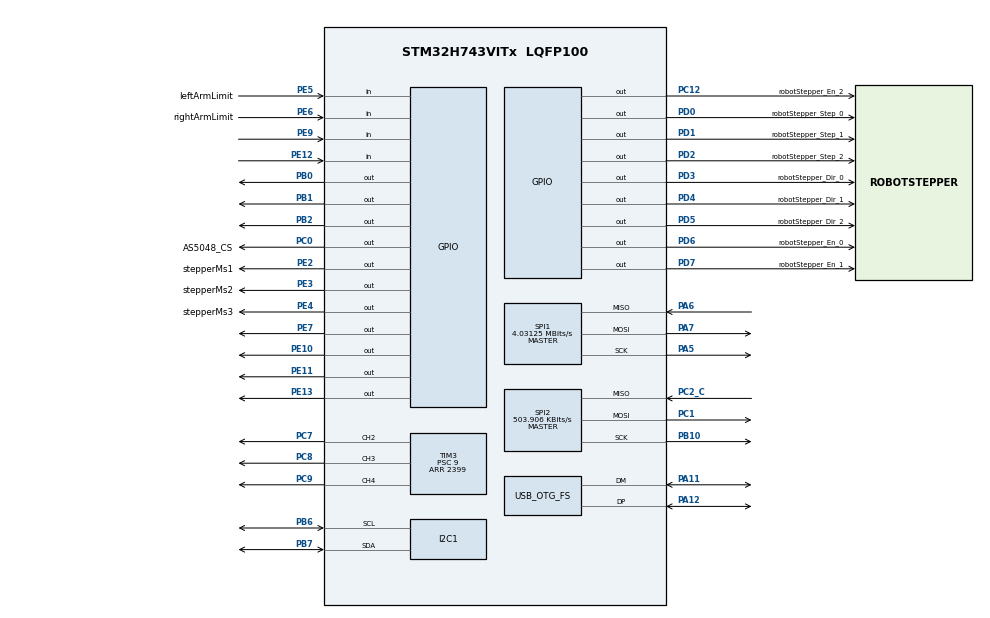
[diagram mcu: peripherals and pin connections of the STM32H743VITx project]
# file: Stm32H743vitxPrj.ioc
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FREERTOS.Tasks01=defaultTask,0,6001,StartDefaultTask,Default,NULL,Dynamic,NULL,NULL
FREERTOS.configMINIMAL_STACK_SIZE=6000
FREERTOS.configTICK_RATE_HZ=100
FREERTOS.configTOTAL_HEAP_SIZE=135360
I2C1.Timing=0x307075B1
Mcu.Family=STM32H7
Mcu.Name=STM32H743VITx
Mcu.Package=LQFP100
NVIC.OTG_FS_IRQn=true\:0\:0\:false\:false\:true\:false\:false\:true
NVIC.PriorityGroup=NVIC_PRIORITYGROUP_4
NVIC.TIM2_IRQn=true\:5\:0\:false\:false\:true\:true\:true\:true
NVIC.TIM5_IRQn=true\:0\:0\:false\:false\:true\:false\:true\:true
NVIC.TimeBase=TIM5_IRQn
NVIC.TimeBaseIP=TIM5
PA11.Mode=Device_Only
PA11.Signal=USB_OTG_FS_DM
PA12.Mode=Device_Only
PA12.Signal=USB_OTG_FS_DP
PA5.Mode=Full_Duplex_Master
PA5.Signal=SPI1_SCK
PA6.Mode=Full_Duplex_Master
PA6.Signal=SPI1_MISO
PA7.Mode=Full_Duplex_Master
PA7.Signal=SPI1_MOSI
PB0.Signal=GPIO_Output
PB1.Signal=GPIO_Output
PB10.Mode=Full_Duplex_Master
PB10.Signal=SPI2_SCK
PB2.Signal=GPIO_Output
PB6.Mode=I2C
PB6.Signal=I2C1_SCL
PB7.Mode=I2C
PB7.Signal=I2C1_SDA
PC0.GPIO_Label=AS5048_CS
PC0.Signal=GPIO_Output
PC1.Mode=Full_Duplex_Master
PC1.Signal=SPI2_MOSI
PC12.GPIO_Label=robotStepper_En_2
PC12.Signal=GPIO_Output
PC14-OSC32_IN\ (OSC32_IN).Mode=LSE-External-Oscillator
PC14-OSC32_IN\ (OSC32_IN).Signal=RCC_OSC32_IN
PC15-OSC32_OUT\ (OSC32_OUT).Mode=LSE-External-Oscillator
PC15-OSC32_OUT\ (OSC32_OUT).Signal=RCC_OSC32_OUT
PC2_C.Mode=Full_Duplex_Master
PC2_C.Signal=SPI2_MISO
PC7.Signal=S_TIM3_CH2
PC8.Signal=S_TIM3_CH3
PC9.Signal=S_TIM3_CH4
PD0.GPIO_Label=robotStepper_Step_0
PD0.Signal=GPIO_Output
PD1.GPIO_Label=robotStepper_Step_1
PD1.Signal=GPIO_Output
PD2.GPIO_Label=robotStepper_Step_2
PD2.Signal=GPIO_Output
PD3.GPIO_Label=robotStepper_Dir_0
PD3.Signal=GPIO_Output
PD4.GPIO_Label=robotStepper_Dir_1
PD4.Signal=GPIO_Output
PD5.GPIO_Label=robotStepper_Dir_2
PD5.Signal=GPIO_Output
PD6.GPIO_Label=robotStepper_En_0
PD6.Signal=GPIO_Output
PD7.GPIO_Label=robotStepper_En_1
PD7.Signal=GPIO_Output
PE10.Signal=GPIO_Output
PE11.Signal=GPIO_Output
PE12.Signal=GPIO_Input
PE13.Signal=GPIO_Output
PE2.GPIO_Label=stepperMs1
PE2.Signal=GPIO_Output
PE3.GPIO_Label=stepperMs2
PE3.Signal=GPIO_Output
PE4.GPIO_Label=stepperMs3
PE4.Signal=GPIO_Output
PE5.GPIO_Label=leftArmLimit
PE5.GPIO_PuPd=GPIO_PULLUP
PE5.Signal=GPIO_Input
PE6.GPIO_Label=rightArmLimit
PE6.GPIO_PuPd=GPIO_PULLUP
PE6.Signal=GPIO_Input
PE7.Signal=GPIO_Output
PE9.Signal=GPIO_Input
PH0-OSC_IN\ (PH0).Mode=HSE-External-Oscillator
PH0-OSC_IN\ (PH0).Signal=RCC_OSC_IN
PH1-OSC_OUT\ (PH1).Mode=HSE-External-Oscillator
PH1-OSC_OUT\ (PH1).Signal=RCC_OSC_OUT
ProjectManager.HeapSize=0x200
ProjectManager.StackSize=0x400
ProjectManager.TargetToolchain=STM32CubeIDE
RCC.ADCFreq_Value=129000000
RCC.APB1Freq_Value=120000000
RCC.APB2Freq_Value=120000000
RCC.APB3Freq_Value=120000000
RCC.APB4Freq_Value=120000000
RCC.CortexFreq_Value=480000000
RCC.D1PPRE=RCC_APB3_DIV2
RCC.D2PPRE1=RCC_APB1_DIV2
RCC.D2PPRE2=RCC_APB2_DIV2
RCC.D3PPRE=RCC_APB4_DIV2
RCC.DIVM1=4
RCC.DIVN1=60
RCC.HCLKFreq_Value=240000000
RCC.HPRE=RCC_HCLK_DIV2
RCC.PLL2FRACN=0
RCC.PLL3FRACN=0
RCC.PLLFRACN=0
RCC.SPI123CLockSelection=RCC_SPI123CLKSOURCE_PLL2
RCC.SYSCLKFreq_VALUE=480000000
RCC.SYSCLKSource=RCC_SYSCLKSOURCE_PLLCLK
RCC.USBCLockSelection=RCC_USBCLKSOURCE_HSI48
RCC.USBFreq_Value=48000000
SH.S_TIM3_CH2.0=TIM3_CH2,PWM Generation2 CH2
SH.S_TIM3_CH3.0=TIM3_CH3,PWM Generation3 CH3
SH.S_TIM3_CH4.0=TIM3_CH4,PWM Generation4 CH4
SPI1.BaudRatePrescaler=SPI_BAUDRATEPRESCALER_32
SPI1.CLKPolarity=SPI_POLARITY_LOW
SPI1.CalculateBaudRate=4.03125 MBits/s
SPI1.DataSize=SPI_DATASIZE_8BIT
SPI1.Direction=SPI_DIRECTION_2LINES
SPI1.MasterKeepIOState=SPI_MASTER_KEEP_IO_STATE_ENABLE
SPI1.Mode=SPI_MODE_MASTER
SPI1.VirtualType=VM_MASTER
SPI2.BaudRatePrescaler=SPI_BAUDRATEPRESCALER_256
SPI2.CalculateBaudRate=503.906 KBits/s
SPI2.DataSize=SPI_DATASIZE_8BIT
SPI2.Direction=SPI_DIRECTION_2LINES
SPI2.MasterKeepIOState=SPI_MASTER_KEEP_IO_STATE_ENABLE
SPI2.Mode=SPI_MODE_MASTER
SPI2.VirtualType=VM_MASTER
TIM2.Period=239
TIM2.Prescaler=99
TIM3.Channel-PWM\ Generation2\ CH2=TIM_CHANNEL_2
TIM3.Channel-PWM\ Generation3\ CH3=TIM_CHANNEL_3
TIM3.Channel-PWM\ Generation4\ CH4=TIM_CHANNEL_4
TIM3.Period=2399
TIM3.Prescaler=9
USB_DEVICE.CLASS_NAME_FS=CDC
USB_DEVICE.VirtualMode-CDC_FS=Cdc
USB_DEVICE.VirtualModeFS=Cdc_FS
USB_OTG_FS.VirtualMode=Device_Only
VP_FREERTOS_VS_CMSIS_V1.Mode=CMSIS_V1
VP_SYS_VS_tim5.Mode=TIM5
VP_TIM2_VS_ClockSourceINT.Mode=Internal
VP_TIM3_VS_ClockSourceINT.Mode=Internal
VP_USB_DEVICE_VS_USB_DEVICE_CDC_FS.Mode=CDC_FS
board=custom

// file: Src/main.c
/* USER CODE BEGIN Header */
/**
  ******************************************************************************
  * @file           : main.c
  * @brief          : Main program body
  ******************************************************************************
  * @attention
  *
  * <h2><center>&copy; Copyright (c) 2020 STMicroelectronics.
  * All rights reserved.</center></h2>
  *
  * This software component is licensed by ST under Ultimate Liberty license
  * SLA0044, the "License"; You may not use this file except in compliance with
  * the License. You may obtain a copy of the License at:
  *                             www.st.com/SLA0044
  *
  ******************************************************************************
  */
/* USER CODE END Header */

#include "main.h"
#include "cmsis_os.h"
#include "i2c.h"
#include "spi.h"
#include "tim.h"
#include "usb_device.h"
#include "gpio.h"

/* USER CODE BEGIN Includes */
#include "pa_CommonLib/src/drv/pa_CommonDrv/pa_CommonDrv.h"
/* USER CODE END Includes */

void SystemClock_Config(void);
void MX_FREERTOS_Init(void);

int main(void)
{

  /* MCU Configuration--------------------------------------------------------*/

  /* Reset of all peripherals, Initializes the Flash interface and the Systick. */
  HAL_Init();

  /* Configure the system clock */
  SystemClock_Config();

  /* Initialize all configured peripherals */
  MX_GPIO_Init();
  MX_I2C1_Init();
  MX_SPI1_Init();
  MX_TIM2_Init();
  MX_TIM3_Init();
  MX_SPI2_Init();

  /* Call init function for freertos objects (in freertos.c) */
  MX_FREERTOS_Init();

  /* Start scheduler */
  osKernelStart();

  /* We should never get here as control is now taken by the scheduler */

  /* Infinite loop */
  while (1)
  {

  }
}

void SystemClock_Config(void)
{
  RCC_OscInitTypeDef RCC_OscInitStruct = {0};
  RCC_ClkInitTypeDef RCC_ClkInitStruct = {0};
  RCC_PeriphCLKInitTypeDef PeriphClkInitStruct = {0};

  /** Supply configuration update enable
  */
  HAL_PWREx_ConfigSupply(PWR_LDO_SUPPLY);
  /** Configure the main internal regulator output voltage
  */
  __HAL_PWR_VOLTAGESCALING_CONFIG(PWR_REGULATOR_VOLTAGE_SCALE0);

  while(!__HAL_PWR_GET_FLAG(PWR_FLAG_VOSRDY)) {}
  /** Macro to configure the PLL clock source
  */
  __HAL_RCC_PLL_PLLSOURCE_CONFIG(RCC_PLLSOURCE_HSI);
  /** Initializes the CPU, AHB and APB busses clocks
  */
  RCC_OscInitStruct.OscillatorType = RCC_OSCILLATORTYPE_HSI48|RCC_OSCILLATORTYPE_HSI;
  RCC_OscInitStruct.HSIState = RCC_HSI_DIV1;
  RCC_OscInitStruct.HSICalibrationValue = RCC_HSICALIBRATION_DEFAULT;
  RCC_OscInitStruct.HSI48State = RCC_HSI48_ON;
  RCC_OscInitStruct.PLL.PLLState = RCC_PLL_ON;
  RCC_OscInitStruct.PLL.PLLSource = RCC_PLLSOURCE_HSI;
  RCC_OscInitStruct.PLL.PLLM = 4;
  RCC_OscInitStruct.PLL.PLLN = 60;
  RCC_OscInitStruct.PLL.PLLP = 2;
  RCC_OscInitStruct.PLL.PLLQ = 2;
  RCC_OscInitStruct.PLL.PLLR = 2;
  RCC_OscInitStruct.PLL.PLLRGE = RCC_PLL1VCIRANGE_3;
  RCC_OscInitStruct.PLL.PLLVCOSEL = RCC_PLL1VCOWIDE;
  RCC_OscInitStruct.PLL.PLLFRACN = 0;
  if (HAL_RCC_OscConfig(&RCC_OscInitStruct) != HAL_OK)
  {
    Error_Handler();
  }
  /** Initializes the CPU, AHB and APB busses clocks
  */
  RCC_ClkInitStruct.ClockType = RCC_CLOCKTYPE_HCLK|RCC_CLOCKTYPE_SYSCLK
                              |RCC_CLOCKTYPE_PCLK1|RCC_CLOCKTYPE_PCLK2
                              |RCC_CLOCKTYPE_D3PCLK1|RCC_CLOCKTYPE_D1PCLK1;
  RCC_ClkInitStruct.SYSCLKSource = RCC_SYSCLKSOURCE_PLLCLK;
  RCC_ClkInitStruct.SYSCLKDivider = RCC_SYSCLK_DIV1;
  RCC_ClkInitStruct.AHBCLKDivider = RCC_HCLK_DIV2;
  RCC_ClkInitStruct.APB3CLKDivider = RCC_APB3_DIV2;
  RCC_ClkInitStruct.APB1CLKDivider = RCC_APB1_DIV2;
  RCC_ClkInitStruct.APB2CLKDivider = RCC_APB2_DIV2;
  RCC_ClkInitStruct.APB4CLKDivider = RCC_APB4_DIV2;

  if (HAL_RCC_ClockConfig(&RCC_ClkInitStruct, FLASH_LATENCY_4) != HAL_OK)
  {
    Error_Handler();
  }
  PeriphClkInitStruct.PeriphClockSelection = RCC_PERIPHCLK_SPI1|RCC_PERIPHCLK_SPI2
                              |RCC_PERIPHCLK_I2C1|RCC_PERIPHCLK_USB;
  PeriphClkInitStruct.PLL2.PLL2M = 32;
  PeriphClkInitStruct.PLL2.PLL2N = 129;
  PeriphClkInitStruct.PLL2.PLL2P = 2;
  PeriphClkInitStruct.PLL2.PLL2Q = 2;
  PeriphClkInitStruct.PLL2.PLL2R = 2;
  PeriphClkInitStruct.PLL2.PLL2RGE = RCC_PLL2VCIRANGE_1;
  PeriphClkInitStruct.PLL2.PLL2VCOSEL = RCC_PLL2VCOWIDE;
  PeriphClkInitStruct.PLL2.PLL2FRACN = 0;
  PeriphClkInitStruct.Spi123ClockSelection = RCC_SPI123CLKSOURCE_PLL2;
  PeriphClkInitStruct.I2c123ClockSelection = RCC_I2C123CLKSOURCE_D2PCLK1;
  PeriphClkInitStruct.UsbClockSelection = RCC_USBCLKSOURCE_HSI48;
  if (HAL_RCCEx_PeriphCLKConfig(&PeriphClkInitStruct) != HAL_OK)
  {
    Error_Handler();
  }
  /** Enable USB Voltage detector
  */
  HAL_PWREx_EnableUSBVoltageDetector();
}

void HAL_TIM_PeriodElapsedCallback(TIM_HandleTypeDef *htim)
{
  /* USER CODE BEGIN Callback 0 */
  if (htim->Instance == TIM2)
  {
    pa_CallBack_100us();
    // tim_1ms_tick();
  }
  /* USER CODE END Callback 0 */
  if (htim->Instance == TIM5) {
    HAL_IncTick();
  }
}

void Error_Handler(void)
{
}

/************************ (C) COPYRIGHT STMicroelectronics *****END OF FILE****/

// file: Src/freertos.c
/* USER CODE BEGIN Header */
/**
  ******************************************************************************
  * File Name          : freertos.c
  * Description        : Code for freertos applications
  ******************************************************************************
  * @attention
  *
  * <h2><center>&copy; Copyright (c) 2020 STMicroelectronics.
  * All rights reserved.</center></h2>
  *
  * This software component is licensed by ST under Ultimate Liberty license
  * SLA0044, the "License"; You may not use this file except in compliance with
  * the License. You may obtain a copy of the License at:
  *                             www.st.com/SLA0044
  *
  ******************************************************************************
  */
/* USER CODE END Header */

#include "FreeRTOS.h"
#include "task.h"
#include "main.h"
#include "cmsis_os.h"

/* USER CODE BEGIN Includes */
#include "pa_CommonLib/src/app/_main_select/_main_select.h"
/* USER CODE END Includes */

osThreadId defaultTaskHandle;

void StartDefaultTask(void const * argument);

extern void MX_USB_DEVICE_Init(void);
void MX_FREERTOS_Init(void); /* (MISRA C 2004 rule 8.1) */

void MX_FREERTOS_Init(void) {

  /* Create the thread(s) */
  /* definition and creation of defaultTask */
  osThreadDef(defaultTask, StartDefaultTask, osPriorityNormal, 0, 6001);
  defaultTaskHandle = osThreadCreate(osThread(defaultTask), NULL);

}

void StartDefaultTask(void const * argument)
{
  /* init code for USB_DEVICE */
  MX_USB_DEVICE_Init();

  /* USER CODE BEGIN StartDefaultTask */
  main_select();
  /* Infinite loop */
  for (;;)
  {
    osDelay(1);
  }
  /* USER CODE END StartDefaultTask */
}

/************************ (C) COPYRIGHT STMicroelectronics *****END OF FILE****/
